VERSION "APEX educational demo 1.0 - synthetic signals, not an OEM protocol"
NS_ :

BS_:
BU_: ECU HMI

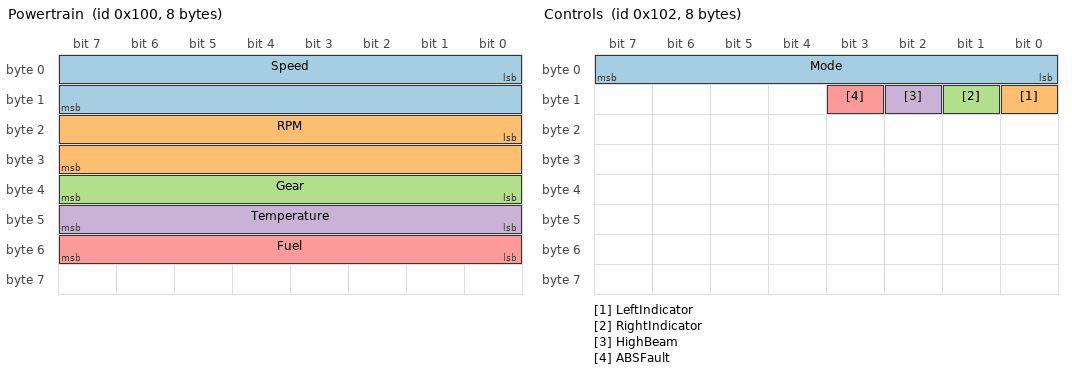
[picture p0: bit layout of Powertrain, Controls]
BO_ 256 Powertrain: 8 ECU
 SG_ Speed : 0|16@1+ (0.01,0) [0|240] "km/h" HMI
 SG_ RPM : 16|16@1+ (1,0) [0|14000] "rpm" HMI
 SG_ Gear : 32|8@1+ (1,0) [0|6] "" HMI
 SG_ Temperature : 40|8@1+ (1,-40) [-40|150] "degC" HMI
 SG_ Fuel : 48|8@1+ (0.5,0) [0|100] "%" HMI

BO_ 257 TirePressure: 8 ECU
 SG_ FrontPressure : 0|16@1+ (0.01,0) [0|5] "bar" HMI
 SG_ RearPressure : 16|16@1+ (0.01,0) [0|5] "bar" HMI

BO_ 258 Controls: 8 ECU
 SG_ Mode : 0|8@1+ (1,0) [0|2] "" HMI
 SG_ LeftIndicator : 8|1@1+ (1,0) [0|1] "" HMI
 SG_ RightIndicator : 9|1@1+ (1,0) [0|1] "" HMI
 SG_ HighBeam : 10|1@1+ (1,0) [0|1] "" HMI
 SG_ ABSFault : 11|1@1+ (1,0) [0|1] "" HMI
